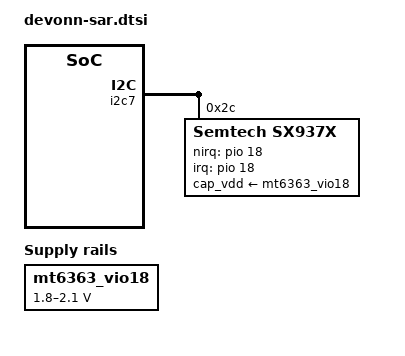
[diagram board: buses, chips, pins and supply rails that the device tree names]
/*
 * Copyright (c) 2021 MediaTek Inc.
 *
 * This program is free software; you can redistribute it and/or modify
 * it under the terms of the GNU General Public License version 2 as
 * published by the Free Software Foundation.
 *
 * This program is distributed in the hope that it will be useful,
 * but WITHOUT ANY WARRANTY; without even the implied warranty of
 * MERCHANTABILITY or FITNESS FOR A PARTICULAR PURPOSE.  See the
 * GNU General Public License for more details.
 */

&pio {
	sar_int_default: sar_int_default {
		pins_cmd_dat {
			pinmux = <PINMUX_GPIO18__FUNC_GPIO18>;
			input-enable;
			drive-strength = <2>;
			bias-pull-up;
		};
	};

	sar_int_sleep: sar_int_sleep {
		pins_cmd_dat {
			pinmux = <PINMUX_GPIO18__FUNC_GPIO18>;
			input-enable;
			drive-strength = <2>;
			bias-pull-up;
		};
	};
};

&mt6363_vio18 {
	regulator-min-microvolt = <1800000>;
	regulator-max-microvolt = <2100000>;
};

&i2c7 {
	status = "okay";

	sx937x:sx937x@2c {
		compatible = "Semtech,sx937x";
		reg = <0x2c>;
		pinctrl-names = "default","sleep";
		pinctrl-0 = <&sar_int_default>;
		pinctrl-1 = <&sar_int_sleep>;
		interrupt-parent = <&pio>;
		interrupts = <18 0x02>;
		interrupt-names = "sx937x_irq";
		Semtech,nirq-gpio = <&pio 18 0x02>;
		cap_vdd-supply = <&mt6363_vio18>;
		/*use PH4/5/6 as the reference sensor
		set it to 0xff if the ref-phases-x is not used*/
		Semtech,ref-phases-a = <5>;
		Semtech,ref-phases-b = <6>;
		Semtech,ref-phases-c = <0xff>;
		Semtech,button-flag = <0x1f>;
		Semtech,reg-num = <64>;
		Semtech,reg-init = <
			0x4004  0x78
			0x4008  0x8
			0x8020  0x32
			0x8028  0x857 		/*AFE_PARAM_PH0*/
			0x8034  0x856 		/*AFE_PARAM_PH1*/
			0x8040  0x856 		/*AFE_PARAM_PH2*/
			0x804C  0x857 		/*AFE_PARAM_PH3*/
			0x8058  0x856 		/*AFE_PARAM_PH4*/
			0x8064  0x856 		/*AFE_PARAM_PH5*/
			0x8070  0x856 		/*AFE_PARAM_PH6*/
			0x807C  0x85E  		/*AFE_PARAM_PH7*/
			/*set CS3 to hiz, because it used as IRQ pin*/
			0x8030  0xFFF9FD 	/*REG_AFEPH_PH0, CS0, ANT0, Bottom center*/
			0x803C  0xFFD9FF 	/*REG_AFEPH_PH1, CS4, ANT8, Top Left*/
			0x8048  0xF7F9FF 	/*REG_AFEPH_PH2, CS6, ANT1, Bottom Right*/
			0x8054  0xBFF9FF 	/*REG_AFEPH_PH3, CS7, ANT4, Top Right*/
			0x8060  0xFEF9FF 	/*REG_AFEPH_PH4, CS5, ANT5, Right*/
			0x806C  0xFFF9EF 	/*REG_AFEPH_PH5, CS1, ANT REF */
			0x8078  0xFFF97F 	/*REG_AFEPH_PH6, CS2, ANT REF */
			0x8084  0xFFFFFF 	/*REG_AFEPH_PH7, NOT USE*/
			0x8098  0x4831
			0x80B8  0x3323
			0x80D8  0x2D23
			0x80F8  0x5B34
			0x8118  0x2E2E
			0x8138  0xC8
			0x8158  0xC8
			0x8178  0xC8
			0x80A0  0x242400E1
			0x80C0  0x262600E2
			0x80E0  0x1F1F00E1
			0x8100  0x202000E0
			0x8120  0x1E1E00E2
			0x8140  0x0
			0x8160  0x0
			0x8180  0x0
			0x8188  0x8000015
			0x818C  0x8000016
			0x8190  0x0
			0x8194  0x0
			0x8090  0x54C45000
			0x80B0  0x2AD87000
			0x80D0  0x54D85000
			0x80F0  0x2AD77000
			0x8110  0x2AD77000
			0x8130  0x2AD67000
			0x8150  0x2AD67000
			0x8170  0x2AD66000
			0x8088  0x300000
			0x80A8  0x300000
			0x80C8  0x300000
			0x80E8  0x300000
			0x8108  0x300000
			0x8128  0x300000
			0x8148  0x300000
			0x8168  0x300000
			0x808C  0x60200018
			0x80AC  0x60200018
			0x80CC  0x60200018
			0x80EC  0x60200018
			0x810C  0x60200018
			0x812C  0x60200018
			0x814C  0x60200018
			0x816C  0x60200018
			0x8024  0x7F7F
		>;

		status = "okay";
	};
};
